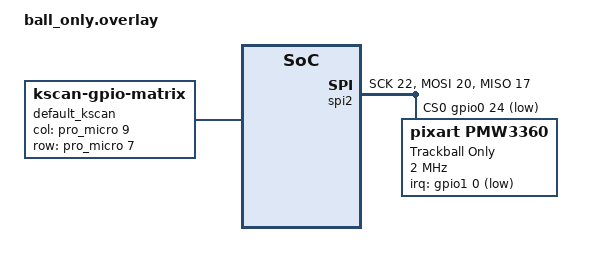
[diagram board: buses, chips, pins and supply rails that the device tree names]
#include <dt-bindings/zmk/matrix_transform.h>

/ {
  chosen {
		zmk,kscan = &default_kscan;
		zmk,matrix_transform = &default_transform;
	};

	default_kscan: kscan {
		compatible = "zmk,kscan-gpio-matrix";
		label = "default_kscan";
		diode-direction = "row2col";

        col-gpios = <&pro_micro 8 (GPIO_ACTIVE_HIGH | GPIO_PULL_DOWN)>;
        col-gpios = <&pro_micro 9 (GPIO_ACTIVE_HIGH | GPIO_PULL_DOWN)>;

        row-gpios = <&pro_micro 7 GPIO_ACTIVE_HIGH>;
	};

	default_transform: keymap_transform_0 {
		compatible = "zmk,matrix-transform";
		columns = <2>;
		rows = <1>;
        map = <RC(0,0) RC(0,1)>;
	};
    trackballs {
		compatible = "zmk,keymap-trackballs";
		trackballs = <&trackball>;
	};
};

&spi2 {
  compatible = "nordic,nrf-spim";
  status = "okay";
  miso-pin = <17>; // P0.17
  mosi-pin = <20>; // P0.20
  sck-pin = <22>; // P0.22
  cs-gpios = <&gpio0 24 GPIO_ACTIVE_LOW>; // P0.24

  trackball: trackball@0 {
      status = "okay";
      compatible = "pixart,pmw3360";
      reg = <0>;
      label = "Trackball Only";
      irq-gpios = <&gpio1 0 (GPIO_ACTIVE_LOW | GPIO_PULL_UP)>;
      spi-max-frequency = <2000000>;
      scroll-layer = <5>;
  };
};
